# HSM_TC3xx register map
Vendor: Infineon; Series: AURIX TC3xx; File version: 2.0
CPU: CM3 r2p0, little endian, MPU, no FPU, 3 interrupt priority bits
Registers are 32-bit, read-write, no defined reset value unless marked. A register's access mark holds for its fields unless they carry their own. Offsets are from the block's base; [hi:lo] are bit positions; lines under a group give offsets from that group; {n}, {i} and the like mark numbered series.

## HSM_HASH — Hash module MD5/SHA-1/SHA-224/SHA-256 (HSM TS 5.3). Only 32-bit accesses; reading a write-only register gives a bus error.
Base 0xE8000400
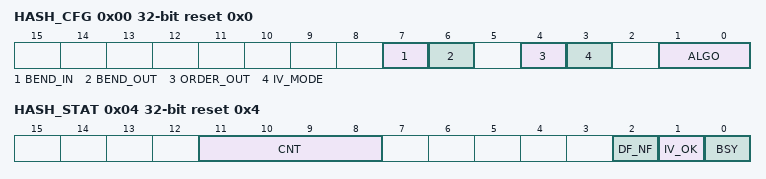
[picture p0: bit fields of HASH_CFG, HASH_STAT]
0x00 HASH_CFG reset 0x0 — HASH Configuration Register
  [7] BEND_IN — Input byte endianness
    0=BIG (MSB left-most); 1=LIT (MSB right-most)
  [6] BEND_OUT — Output byte endianness
    0=BIG (MSB left-most); 1=LIT (MSB right-most)
  [4] ORDER_OUT — Output word order
    0=LSW_FIRST (Least significant word first); 1=MSW_FIRST (Most significant word first)
  [3] IV_MODE — Initialization value mode
    0=NO_IV (Default starting state); 1=USE_IV (Start from HASH_IVIN value)
  [1:0] ALGO — Hash algorithm
    0=NONE (No hash function); 1=MD5; 2=SHA1; 3=SHA256
0x04 HASH_STAT ro reset 0x4 — HASH Status Register
  [11:8] CNT — Result counter: 32-bit words left in HASH_VAL
  [2] DF_NF — Data FIFO not full
    0=FIFO_FULL; 1=FIFO_NOTFULL (Data can be written)
  [1] IV_OK — Initialization vector valid
  [0] BSY — Busy flag
    0=HASH_IDLE (No operation); 1=HASH_BUSY (Hashing or initialization ongoing)
0x08 HASH_IVIN wo reset 0x0 — Hash Initialization Value Register (consecutive writes; a read gives a bus error)
  [31:0] HASH_INIT_VEC — Initialization value word
0x0C HASH_VAL ro reset 0x0 read-modifies — Hash Output Value Register. Each read returns the next result word and decrements HASH_STAT.CNT, so it is not read automatically.
  [31:0] HASH_VAL — Hash output word
0x10 HASH_DATA wo reset 0x0 — Hash Data Input Register (fills the FIFO; a read gives a bus error)
  [31:0] HASH_DATA — Input data word

## HSM_PKC — Public Key Cryptography module, control and status (HSM TS 6.4.1). Only 32-bit accesses.
Base 0xE8003C00
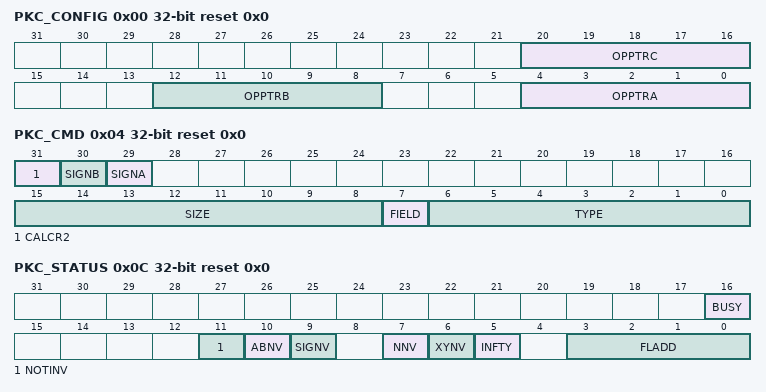
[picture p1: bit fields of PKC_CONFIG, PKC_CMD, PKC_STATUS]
0x00 PKC_CONFIG reset 0x0 — PKC Configuration Register (operand pointers into the SCM)
  [20:16] OPPTRC — Pointer for operand/result C (PKC_SCM_Ri)
  [12:8] OPPTRB — Pointer for operand B (PKC_SCM_Ri)
  [4:0] OPPTRA — Pointer for operand A (PKC_SCM_Ri)
0x04 PKC_CMD reset 0x0 — PKC Command Register
  [31] CALCR2 — Calculate R^2 mod N before the next operation (cleared by hardware)
  [30] SIGNB — Sign of parameter b in Y^2 = X^3 +- aX +- b (1: negative)
  [29] SIGNA — Sign of parameter a in Y^2 = X^3 +- aX +- b (1: negative)
  [15:8] SIZE — Operand size in multiples of 64 bits (1-4)
  [7] FIELD
    0=Z (Z or Z/p); 1=F2X (F2[X] or F2[X]/(f))
  [6:0] TYPE — Type of operation
    1=ADDN (Modular addition); 2=SUBN (Modular subtraction); 3=MULTN (Modular multiplication); 4=RED (Modular reduction); 5=DIVN (Modular division); 6=INV (Modular inversion); 8=MULT (Multiplication); 9=INV2 (Modular inversion (n even)); 10=RED2 (Modular reduction (n even)); 16=EXP (Modular exponentiation); 32=PDBL (Point doubling); 33=PADD (Point addition); 34=SMULT (Scalar multiplication); 35=CHECKAB (Check parameters a, b); 36=CHECKN (Check order n); 37=CHECKPXY (Check point coordinates); 40=SMULT25519 (Scalar multiplication Curve25519); 41=XRECOVER (X coordinate recovery Ed25519); 42=SMULTED25519 (Scalar multiplication Ed25519); 43=CHECKVALID (Check S*PB = h*PA + PR)
0x08 PKC_CTRL reset 0x0 — PKC Control Register
  [0] START — Start the command in PKC_CMD (cleared when finished)
0x0C PKC_STATUS ro reset 0x0
  [16] BUSY — PKC busy: no SCM access allowed
  [11] NOTINV — Parameter not invertible
  [10] ABNV — Parameters a, b not valid
  [9] SIGNV — Signature not valid
  [7] NNV — Parameter n (curve order) not valid
  [6] XYNV — Coordinates not reduced
  [5] INFTY — Point at infinity occurred
  [3:0] FLADD — Fail address of the last invalid point

## HSM_PKC_SCM — PKC Shared Crypto Memory: 32 long integer registers of 256 bits (HSM TS 6.4.2). Only expand while PKC_STATUS.BUSY = 0: the SCM must not be accessed while the PKC is working.
Base 0xE8004000
{0x0+0x20*i} R{i} group (i=0..31) — Shared crypto memory register {i} (W0 = bits 31:0 ... W7 = bits 255:224)
  {0x0+4j} W{j} (j=0..7) — Word {j}
    [31:0] DATA — Parameters, keys, operands or results
